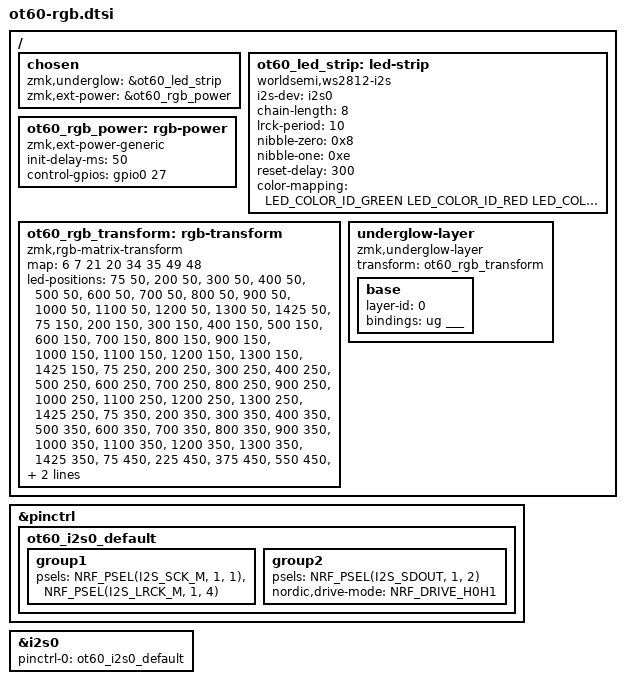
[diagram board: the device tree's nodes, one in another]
/* SPDX-License-Identifier: MIT */

#include <dt-bindings/led/led.h>
#include <dt-bindings/zmk/rgb_colors.h>

&pinctrl {
    ot60_i2s0_default: ot60_i2s0_default {
        group1 {
            /* The I2S clocks use pins that have no board connections. */
            psels = <NRF_PSEL(I2S_SCK_M, 1, 1)>, <NRF_PSEL(I2S_LRCK_M, 1, 4)>;
        };
        group2 {
            psels = <NRF_PSEL(I2S_SDOUT, 1, 2)>;
            nordic,drive-mode = <NRF_DRIVE_H0H1>;
        };
    };
};

&i2s0 {
    status = "okay";
    pinctrl-0 = <&ot60_i2s0_default>;
    pinctrl-names = "default";
};

/ {
    chosen {
        zmk,underglow = &ot60_led_strip;
        zmk,ext-power = &ot60_rgb_power;
    };

    ot60_led_strip: led-strip {
        compatible = "worldsemi,ws2812-i2s";
        i2s-dev = <&i2s0>;
        chain-length = <8>;
        /* 3.2 MHz serial clock gives 1.25 us per SK6812 bit. */
        lrck-period = <10>;
        nibble-zero = <0x8>;
        nibble-one = <0xe>;
        reset-delay = <300>;
        color-mapping = <LED_COLOR_ID_GREEN LED_COLOR_ID_RED LED_COLOR_ID_BLUE>;
    };

    ot60_rgb_power: rgb-power {
        compatible = "zmk,ext-power-generic";
        init-delay-ms = <50>;
        control-gpios = <&gpio0 27 GPIO_ACTIVE_HIGH>;
    };

    ot60_rgb_transform: rgb-transform {
        compatible = "zmk,rgb-matrix-transform";
        /* RGB1–RGB8 in wire order, mapped to zero-based key positions. */
        map = <6 7 21 20 34 35 49 48>;
        led-positions =
            <  75  50>, < 200  50>, < 300  50>, < 400  50>, < 500  50>, < 600  50>, < 700  50>, < 800  50>, < 900  50>, <1000  50>, <1100  50>, <1200  50>, <1300  50>, <1425  50>,
            <  75 150>, < 200 150>, < 300 150>, < 400 150>, < 500 150>, < 600 150>, < 700 150>, < 800 150>, < 900 150>, <1000 150>, <1100 150>, <1200 150>, <1300 150>, <1425 150>,
            <  75 250>, < 200 250>, < 300 250>, < 400 250>, < 500 250>, < 600 250>, < 700 250>, < 800 250>, < 900 250>, <1000 250>, <1100 250>, <1200 250>, <1300 250>, <1425 250>,
            <  75 350>, < 200 350>, < 300 350>, < 400 350>, < 500 350>, < 600 350>, < 700 350>, < 800 350>, < 900 350>, <1000 350>, <1100 350>, <1200 350>, <1300 350>, <1425 350>,
            <  75 450>, < 225 450>, < 375 450>, < 550 450>, < 750 450>, < 950 450>, <1125 450>, <1275 450>, <1425 450>;
    };

    underglow-layer {
        compatible = "zmk,underglow-layer";
        transform = <&ot60_rgb_transform>;

        base {
            layer-id = <0>;
            /* Use the global effect until individual colors are assigned in Studio. */
            bindings = <&ug ___>;
        };
    };
};
